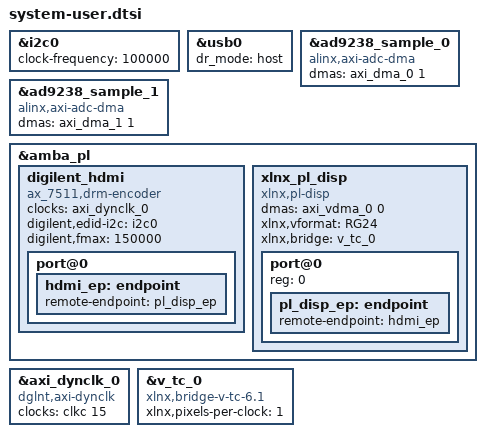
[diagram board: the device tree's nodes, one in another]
/include/ "system-conf.dtsi"
/ {




};


&i2c0 {
	clock-frequency = <100000>;

};

&usb0 {	
	dr_mode = "host";

};



&ad9238_sample_0 {
	compatible = "alinx,axi-adc-dma";
	dmas = <&axi_dma_0 1>;
	dma-names = "axidma1";
};

&ad9238_sample_1 {
	compatible = "alinx,axi-adc-dma";
	dmas = <&axi_dma_1 1>;
	dma-names = "axidma1";
};


&amba_pl {

	digilent_hdmi {
		compatible = "ax_7511,drm-encoder";

		clocks = <&axi_dynclk_0>;
		clock-names = "clk";

		digilent,edid-i2c = <&i2c0>;
		digilent,fmax = <150000>;
		
		port@0 {
			#address-cells = <1>;
			#size-cells = <0>;

			hdmi_ep: endpoint {
				remote-endpoint = <&pl_disp_ep>;
			};
		};
	};
	
	xlnx_pl_disp {
		compatible = "xlnx,pl-disp";
		dmas = <&axi_vdma_0 0>;
		dma-names = "dma0";

		xlnx,vformat = "RG24";
		xlnx,bridge = <&v_tc_0>;

		port@0 {
			reg = <0>;
			pl_disp_ep: endpoint {
				remote-endpoint = <&hdmi_ep>;
			};
		};
	};


	
};

&axi_dynclk_0 {
	compatible = "dglnt,axi-dynclk";
	#clock-cells = <0>;
	clocks = <&clkc 15>;
};
&v_tc_0 {
	compatible = "xlnx,bridge-v-tc-6.1";
	xlnx,pixels-per-clock = <1>;
};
